# CBASS_DBG_CBASS_DBG_ERR_00200000h register map
Vendor: Texas Instruments
Peripheral module from a debugger description file (folder am62L).
Registers are 32-bit, read-only, reset 0x0 unless marked. A register's access mark holds for its fields unless they carry their own. Offsets are as the file gives them; lines under a group give offsets from that group; [hi:lo] are bit positions; {n}, {i} and the like mark numbered series; 'fields as' and 'values as' point back to an identical list; <NAME> marks a mode.

## CBASS_DBG_ERR
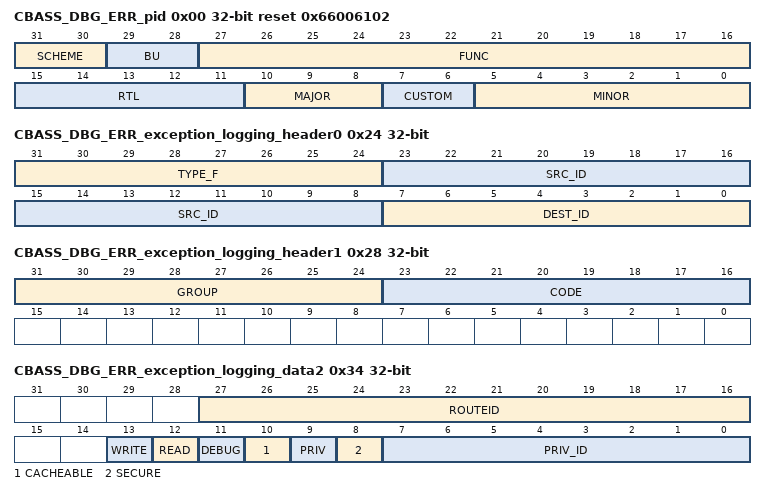
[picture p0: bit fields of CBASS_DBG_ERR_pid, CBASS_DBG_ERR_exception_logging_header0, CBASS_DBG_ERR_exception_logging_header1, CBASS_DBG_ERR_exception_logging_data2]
0x00 CBASS_DBG_ERR_pid reset 0x66006102 — The Revision Register contains the major and minor revisions for the module.
  [31:30] SCHEME — PID register scheme Reset Source: SCRP_maindbg_PERCLK4_rst_mod_g_rst_n
  [29:28] BU — Business Unit: 10 = Processors Reset Source: SCRP_maindbg_PERCLK4_rst_mod_g_rst_n
  [27:16] FUNC — Module ID Reset Source: SCRP_maindbg_PERCLK4_rst_mod_g_rst_n
  [15:11] RTL — RTL revision. Will vary depending on release. Reset Source: SCRP_maindbg_PERCLK4_rst_mod_g_rst_n
  [10:8] MAJOR — Major revision Reset Source: SCRP_maindbg_PERCLK4_rst_mod_g_rst_n
  [7:6] CUSTOM — Custom Reset Source: SCRP_maindbg_PERCLK4_rst_mod_g_rst_n
  [5:0] MINOR — Minor revision Reset Source: SCRP_maindbg_PERCLK4_rst_mod_g_rst_n
0x04 CBASS_DBG_ERR_destination_id rw — The Destination ID Register defines the destination ID value for error messages.
  [7:0] DEST_ID — The destination ID. Reset Source: SCRP_maindbg_PERCLK4_rst_mod_g_rst_n
0x24 CBASS_DBG_ERR_exception_logging_header0 — The Exception Logging Header 0 Register contains the first word of the header.
  [31:24] TYPE_F — Type. 7 = CBASS. Reset Source: SCRP_maindbg_PERCLK4_rst_mod_g_rst_n
  [23:8] SRC_ID — Source ID. Always 0. Reset Source: SCRP_maindbg_PERCLK4_rst_mod_g_rst_n
  [7:0] DEST_ID — Destination ID. Reset Source: SCRP_maindbg_PERCLK4_rst_mod_g_rst_n
0x28 CBASS_DBG_ERR_exception_logging_header1 — The Exception Logging Header 1 Register contains the second word of the header.
  [31:24] GROUP — Group. Always 0. Reset Source: SCRP_maindbg_PERCLK4_rst_mod_g_rst_n
  [23:16] CODE — Code. 0 = CBASS decode error. Reset Source: SCRP_maindbg_PERCLK4_rst_mod_g_rst_n
0x2C CBASS_DBG_ERR_exception_logging_data0 — The Exception Logging Data 0 Register contains the first word of the data.
  [31:0] ADDR_L — Address lower 32 bits. Reset Source: SCRP_maindbg_PERCLK4_rst_mod_g_rst_n
0x30 CBASS_DBG_ERR_exception_logging_data1 — The Exception Logging Data 1 Register contains the second word of the data.
  [15:0] ADDR_H — Address upper 16 bits. Reset Source: SCRP_maindbg_PERCLK4_rst_mod_g_rst_n
0x34 CBASS_DBG_ERR_exception_logging_data2 — The Exception Logging Data 2 Register contains the third word of the data.
  [27:16] ROUTEID — Route ID. Reset Source: SCRP_maindbg_PERCLK4_rst_mod_g_rst_n
  [13] WRITE — Write. Reset Source: SCRP_maindbg_PERCLK4_rst_mod_g_rst_n
  [12] READ — Read. Reset Source: SCRP_maindbg_PERCLK4_rst_mod_g_rst_n
  [11] DEBUG — Debug. Reset Source: SCRP_maindbg_PERCLK4_rst_mod_g_rst_n
  [10] CACHEABLE — Cacheable. Reset Source: SCRP_maindbg_PERCLK4_rst_mod_g_rst_n
  [9] PRIV — Priv. Reset Source: SCRP_maindbg_PERCLK4_rst_mod_g_rst_n
  [8] SECURE — Secure. Reset Source: SCRP_maindbg_PERCLK4_rst_mod_g_rst_n
  [7:0] PRIV_ID — Priv ID. Reset Source: SCRP_maindbg_PERCLK4_rst_mod_g_rst_n
0x38 CBASS_DBG_ERR_exception_logging_data3 — The Exception Logging Data 3 Register contains the fourth word of the data.
  [9:0] BYTECNT — Byte count. Reset Source: SCRP_maindbg_PERCLK4_rst_mod_g_rst_n
0x50 CBASS_DBG_ERR_err_intr_raw_stat access not given — The interrupt raw status register indicates if there is null interrupt regardless of interrupt enable
  [0] INTR — Level Interrupt status Reset Source: SCRP_maindbg_PERCLK4_rst_mod_g_rst_n (access R/W1TS)
0x54 CBASS_DBG_ERR_err_intr_enabled_stat access not given — The interrupt status register is gated by the interrupt enable
  [0] ENABLED_INTR — Level Enabled Interrupt status Reset Source: SCRP_maindbg_PERCLK4_rst_mod_g_rst_n (access R/W1TC)
0x58 CBASS_DBG_ERR_err_intr_enable_set access not given — Only when this register is set, null access will cause interrupt to be generated.
  [0] INTR_ENABLE_SET — Interrupt Enable Set Register Reset Source: SCRP_maindbg_PERCLK4_rst_mod_g_rst_n (access R/W1TS)
0x5C CBASS_DBG_ERR_err_intr_enable_clr access not given — Setting this register disables the null interrupt generation
  [0] INTR_ENABLE_CLR — Interrupt Enable Clear Register Reset Source: SCRP_maindbg_PERCLK4_rst_mod_g_rst_n (access R/W1TC)
0x60 CBASS_DBG_ERR_eoi rw — Writing to EOI Register indicates that current interrupt has been serviced which then allows next interrupt to be generated
  [15:0] EOI_WR — End Of Interrupt Register Reset Source: SCRP_maindbg_PERCLK4_rst_mod_g_rst_n
